# CH32H417 register map
Vendor: WCH Ltd.; File version: 1.2
Registers are 32-bit, read-write, reset 0x0 unless marked. A register's access mark holds for its fields unless they carry their own. Offsets are from the block's base; [hi:lo] are bit positions.

## ETHERNET_MAC — Ethernet: media access control
Base 0x40028000
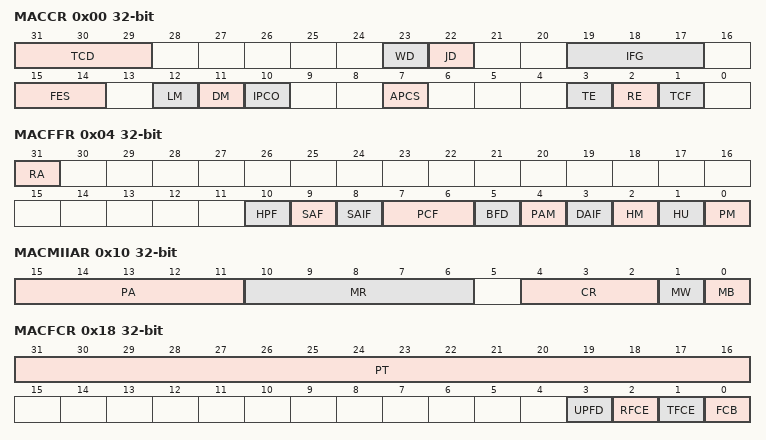
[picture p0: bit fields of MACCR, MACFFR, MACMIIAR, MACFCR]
0x00 MACCR — Ethernet MAC configuration register (ETH_MACCR)
  [31:29] TCD — SEND clock delay
  [23] WD — Watchdog disable
  [22] JD — Jabber disable
  [19:17] IFG — Interframe gap
  [15:14] FES — Fast Ethernet speed
  [12] LM — Loopback mode
  [11] DM — Duplex mode
  [10] IPCO — IPv4 checksum offload
  [7] APCS — Automatic pad/CRC stripping
  [3] TE — Transmitter enable
  [2] RE — Receiver enable
  [1] TCF — Send clock reversal
0x04 MACFFR — Ethernet MAC frame filter register (ETH_MACCFFR)
  [31] RA — Receive all
  [10] HPF — Hash or perfect filter
  [9] SAF — Source address filter
  [8] SAIF — Source address inverse filtering
  [7:6] PCF — Pass control frames
  [5] BFD — Broadcast frames disable
  [4] PAM — Pass all multicast
  [3] DAIF — Destination address inverse filtering
  [2] HM — Hash multicast
  [1] HU — Hash unicast
  [0] PM — Promiscuous mode
0x08 MACHTHR — Ethernet MAC hash table high register
  [31:0] HTH — Hash table high
0x0C MACHTLR — Ethernet MAC hash table low register
  [31:0] HTL — Hash table low
0x10 MACMIIAR — Ethernet MAC MII address register (ETH_MACMIIAR)
  [15:11] PA — PHY address
  [10:6] MR — MII register
  [4:2] CR — Clock range
  [1] MW — MII write
  [0] MB — MII busy
0x14 MACMIIDR — Ethernet MAC MII data register (ETH_MACMIIDR)
  [15:0] MD — MII data
0x18 MACFCR — Ethernet MAC flow control register (ETH_MACFCR)
  [31:16] PT — Pass control frames
  [3] UPFD — Unicast pause frame detect
  [2] RFCE — Receive flow control enable
  [1] TFCE — Transmit flow control enable
  [0] FCB — Flow control busy
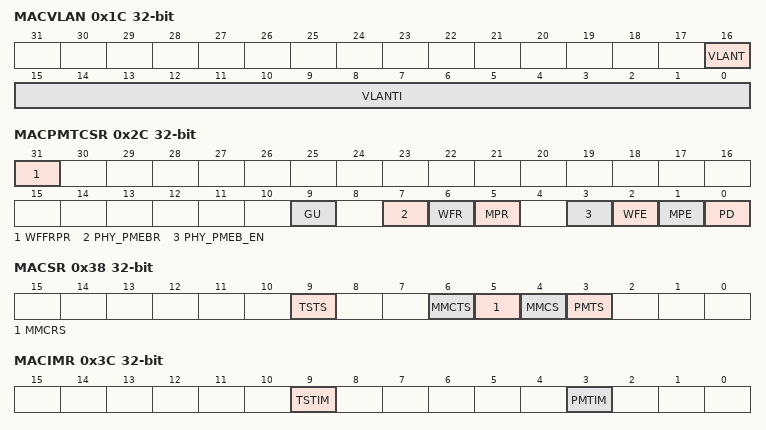
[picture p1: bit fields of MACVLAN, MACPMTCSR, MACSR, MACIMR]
0x1C MACVLAN — Ethernet MAC VLAN tag register (ETH_MACVLAN)
  [16] VLANT — VLAN tag comparison
  [15:0] VLANTI — VLAN tag identifier (for receive frames)
0x28 MACRWUFFR — Ethernet MAC remote wakeup frame filter register (ETH_MACRWUFFR)
  [31:0] RWUFFR — wakeup frame filter
0x2C MACPMTCSR — Ethernet MAC PMT control and status register (ETH_MACPMTCSR)
  [31] WFFRPR — Wakeup frame filter register pointer reset
  [9] GU — Global unicast
  [7] PHY_PMEBR — PHY_PMEB reset
  [6] WFR — Wakeup frame received
  [5] MPR — Magic packet received
  [3] PHY_PMEB_EN — PHY_PMEB enable
  [2] WFE — Wakeup frame enable
  [1] MPE — Magic Packet enable
  [0] PD — Power down
0x38 MACSR — Ethernet MAC interrupt status register (ETH_MACSR)
  [9] TSTS — Time stamp trigger status
  [6] MMCTS — MMC transmit status
  [5] MMCRS — MMC receive status
  [4] MMCS — MMC status
  [3] PMTS — PMT status
0x3C MACIMR — Ethernet MAC interrupt mask register (ETH_MACIMR)
  [9] TSTIM — Time stamp trigger interrupt mask
  [3] PMTIM — PMT interrupt mask
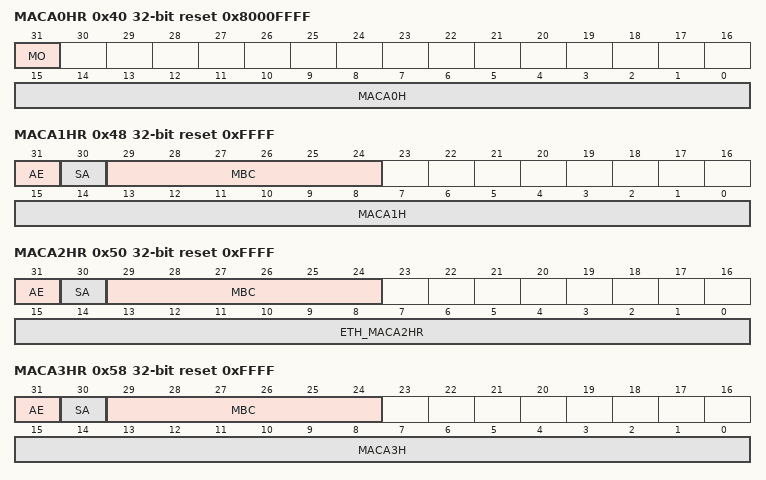
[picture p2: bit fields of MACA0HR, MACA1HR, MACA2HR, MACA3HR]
0x40 MACA0HR access per field reset 0x8000FFFF — Ethernet MAC address 0 high register (ETH_MACA0HR)
  [31] MO ro — Always 1
  [15:0] MACA0H rw — MAC address0 high
0x44 MACA0LR reset 0xFFFFFFFF — Ethernet MAC address 0 low register
  [31:0] MACA0L — MAC address0 low
0x48 MACA1HR reset 0xFFFF — Ethernet MAC address 1 high register (ETH_MACA1HR)
  [31] AE — Address enable
  [30] SA — Source address
  [29:24] MBC — Mask byte control
  [15:0] MACA1H — MAC address1 high
0x4C MACA1LR reset 0xFFFFFFFF — Ethernet MAC address1 low register
  [31:0] MACA1L — MAC address1 low
0x50 MACA2HR reset 0xFFFF — Ethernet MAC address 2 high register (ETH_MACA2HR)
  [31] AE — Address enable
  [30] SA — Source address
  [29:24] MBC — Mask byte control
  [15:0] ETH_MACA2HR — Ethernet MAC address 2 high register
0x54 MACA2LR reset 0xFFFFFFFF — Ethernet MAC address 2 low register
  [31:0] MACA2L — MAC address2 low
0x58 MACA3HR reset 0xFFFF — Ethernet MAC address 3 high register (ETH_MACA3HR)
  [31] AE — Address enable
  [30] SA — Source address
  [29:24] MBC — Mask byte control
  [15:0] MACA3H — MAC address3 high
0x5C MACA3LR reset 0xFFFFFFFF — Ethernet MAC address 3 low register
  [31:0] MBCA3L — MAC address3 low
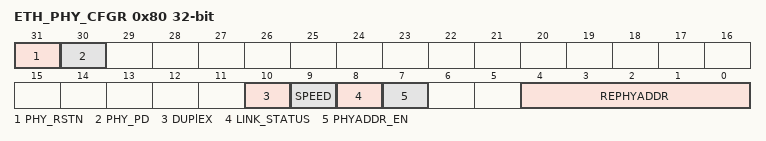
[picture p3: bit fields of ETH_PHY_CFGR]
0x80 ETH_PHY_CFGR access per field — ETH PHY configure register
  [31] PHY_RSTN rw — ETH PHY global reset control
  [30] PHY_PD rw — PHY power-down mode
  [10] DUPlEX ro — connected mode
  [9] SPEED ro — speed selection
  [8] LINK_STATUS ro
  [7] PHYADDR_EN rw — reconfigure the PHY address
  [4:0] REPHYADDR rw — when the bit7 set 1,bit4:0 as PHY address
